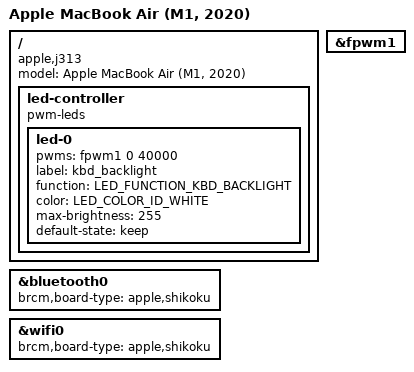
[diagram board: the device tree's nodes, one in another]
// SPDX-License-Identifier: GPL-2.0+ OR MIT
/*
 * Apple MacBook Air (M1, 2020)
 *
 * target-type: J313
 *
 * Copyright The Asahi Linux Contributors
 */

/dts-v1/;

#include "t8103.dtsi"
#include "t8103-jxxx.dtsi"
#include <dt-bindings/leds/common.h>

/ {
	compatible = "apple,j313", "apple,t8103", "apple,arm-platform";
	model = "Apple MacBook Air (M1, 2020)";

	led-controller {
		compatible = "pwm-leds";
		led-0 {
			pwms = <&fpwm1 0 40000>;
			label = "kbd_backlight";
			function = LED_FUNCTION_KBD_BACKLIGHT;
			color = <LED_COLOR_ID_WHITE>;
			max-brightness = <255>;
			default-state = "keep";
		};
	};
};

&bluetooth0 {
	brcm,board-type = "apple,shikoku";
};

&wifi0 {
	brcm,board-type = "apple,shikoku";
};

&fpwm1 {
	status = "okay";
};
